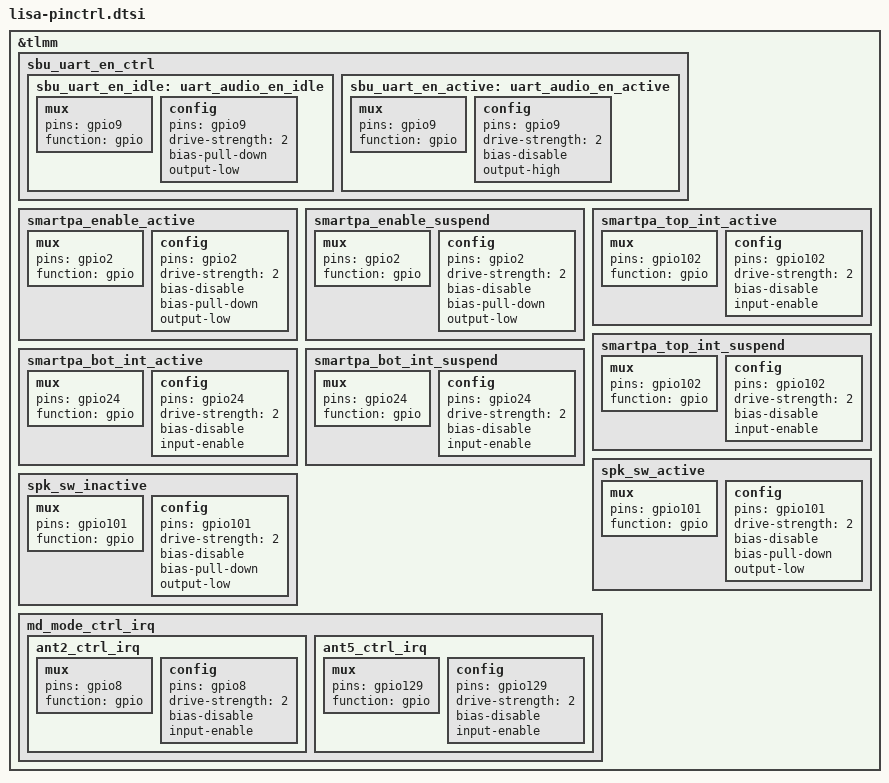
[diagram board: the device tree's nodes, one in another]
/*for lisa pinctrl */
&tlmm {
	sbu_uart_en_ctrl {
		sbu_uart_en_idle: uart_audio_en_idle {
			mux {
				pins = "gpio9";
				function = "gpio";
			};
			config {
				pins = "gpio9";
				drive-strength = <2>;
				bias-pull-down;
				output-low;
			};
		};

		sbu_uart_en_active: uart_audio_en_active {
			mux {
				pins = "gpio9";
				function = "gpio";
			};
			config {
				pins = "gpio9";
				drive-strength = <2>;
				bias-disable;
				output-high;
			};
		};
	};
        smartpa_enable_active: smartpa_enable_active {
		/* active state */
		mux {
		/* GPIO 2 rst pin */
			pins = "gpio2";
			function = "gpio";
		};

		config {
			pins = "gpio2";
			drive-strength = <2>;
			bias-disable;
			bias-pull-down;
			output-low;
		};
	};

	smartpa_enable_suspend: smartpa_enable_suspend {
		/* sleep state */
		mux {
			/* GPIO 2 rst pin */
			pins = "gpio2";
			function = "gpio";
		};

		config {
			pins = "gpio2";
			drive-strength = <2>;
			bias-disable;
			bias-pull-down;
			output-low;
		};
	};

	smartpa_top_int_active: smartpa_top_int_active {
		/* active state */
		mux {
		/* GPIO 102 Interrupt */
			pins = "gpio102";
			function = "gpio";
		};

		config {
			pins = "gpio102";
			drive-strength = <2>; /* 2 MA */
			bias-disable;
			input-enable;
		};
	};

	smartpa_top_int_suspend: smartpa_top_int_suspend {
		/* sleep state */
		mux {
		/* GPIO 102 Interrupt */
			pins = "gpio102";
			function = "gpio";
		};

		config {
			pins = "gpio102";
			drive-strength = <2>; /* 2 MA */
			bias-disable;
			input-enable;
		};
	};

	smartpa_bot_int_active: smartpa_bot_int_active {
		/* active state */
		mux {
		/* GPIO 24 Interrupt */
			pins = "gpio24";
			function = "gpio";
		};

		config {
			pins = "gpio24";
			drive-strength = <2>; /* 2 MA */
			bias-disable;
			input-enable;
		};
	};

	smartpa_bot_int_suspend: smartpa_bot_int_suspend {
		/* sleep state */
		mux {
		/* GPIO 24 Interrupt */
			pins = "gpio24";
			function = "gpio";
		};

		config {
			pins = "gpio24";
			drive-strength = <2>; /* 2 MA */
			bias-disable;
			input-enable;
		};
	};

	/* speaker switch */
	spk_sw_active: spk_sw_active {
		mux {
			pins = "gpio101";
			function = "gpio";
		};

		config {
			pins = "gpio101";
			drive-strength = <2>;
			bias-disable;
			bias-pull-down;
			output-low;
		};
	};

	spk_sw_inactive: spk_sw_inactive {
		mux {
			pins = "gpio101";
			function = "gpio";
		};

		config {
			pins = "gpio101";
			drive-strength = <2>;
			bias-disable;
			bias-pull-down;
			output-low;
		};
	};

        md_mode_ctrl_irq {
		ant2_ctrl_irq: ant2_ctrl_irq {
			mux {
				pins = "gpio8";
				function = "gpio";
			};
			config {
				pins = "gpio8";
				drive-strength = <2>;
				bias-disable;
				input-enable;
			};
		};
		ant5_ctrl_irq: ant5_ctrl_irq {
			mux {
				pins = "gpio129";
				function = "gpio";
			};
			config {
				pins = "gpio129";
				drive-strength = <2>;
				bias-disable;
				input-enable;
			};
		};
	};
};
